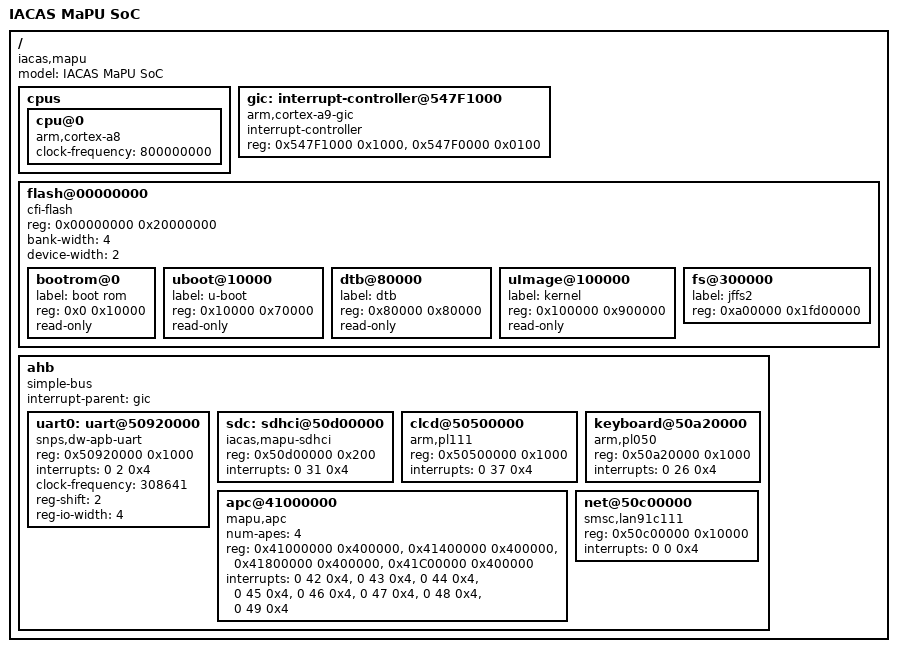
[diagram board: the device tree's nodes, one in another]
/*
 *  Copyright (C) 2014 IACAS, Lei Wang
 *
 * This software is licensed under the terms of the GNU General Public
 * License version 2, as published by the Free Software Foundation, and
 * may be copied, distributed, and modified under those terms.
 *
 * This program is distributed in the hope that it will be useful,
 * but WITHOUT ANY WARRANTY; without even the implied warranty of
 * MERCHANTABILITY or FITNESS FOR A PARTICULAR PURPOSE.  See the
 * GNU General Public License for more details.
 */
/dts-v1/;
/include/ "skeleton.dtsi"
/ {
	model = "IACAS MaPU SoC";
	compatible = "iacas,mapu";
	#address-cells = <1>;
	#size-cells = <1>;

	cpus {
		#address-cells = <1>;
		#size-cells = <0>;

		cpu@0 {
			compatible = "arm,cortex-a8";
			clock-frequency = <800000000>;
		};
	};

  gic: interrupt-controller@547F1000 {
		compatible = "arm,cortex-a9-gic";
		interrupt-controller;
		#interrupt-cells = <3>;
		reg = <0x547F1000 0x1000>,
			    <0x547F0000 0x0100>;
	};
	
	flash@00000000 {
		compatible = "cfi-flash";
		reg = <0x00000000 0x20000000>;
		bank-width = <4>;
		device-width = <2>;
		#address-cells = <1>;
		#size-cells = <1>;
		bootrom@0 {
			label = "boot rom";
			reg = <0x0 0x10000>;
			read-only;
		};
		uboot@10000 {
			label ="u-boot";
			reg = <0x10000 0x70000>;
			read-only;
		};
		dtb@80000 {
			label ="dtb";
			reg = <0x80000 0x80000>;
			read-only;
		};
		uImage@100000 {
			label ="kernel";
			reg = <0x100000 0x900000>;
			read-only;
		};
		fs@300000 {
			label ="jffs2";
			reg = <0xa00000 0x1fd00000>;
		};
	};
	
	ahb {
		compatible = "simple-bus";
		#address-cells = <1>;
		#size-cells = <1>;
    interrupt-parent = <&gic>;
		ranges;
/*
	  uart0: uart@50900000 {
		  compatible = "snps,dw-apb-uart";
		  reg = <0x50900000 0x1000>;
		  interrupts = <0 2 0x4>;
		  clock-frequency = <308641>;
		  reg-shift = <2>;
			reg-io-width = <4>;
		};
*/
/* Match MaPU chip*/
    uart0: uart@50920000 {
      compatible = "snps,dw-apb-uart";
      reg = <0x50920000 0x1000>;
      interrupts = <0 2 0x4>;
      clock-frequency = <308641>;
      reg-shift = <2>;
      reg-io-width = <4>;
    };
    sdc: sdhci@50d00000 {
	    compatible = "iacas,mapu-sdhci";
	    reg = <0x50d00000 0x200>;
			interrupts = <0 31 0x4>;
		};
  
    clcd@50500000 {
      compatible = "arm,pl111", "arm,primecell";
      reg = <0x50500000 0x1000>;
      interrupts = <0 37 0x4>;
    };
    
    keyboard@50a20000 {
      compatible = "arm,pl050", "arm,primecell";
      reg = <0x50a20000 0x1000>;
      interrupts = <0 26 0x4>;
    };
    
    apc@41000000 {
      compatible = "mapu,apc";
      num-apes = <4>;
      reg = <0x41000000 0x400000>, <0x41400000 0x400000>, <0x41800000 0x400000>, <0x41C00000 0x400000>;
      interrupts = <0 42 0x4>, <0 43 0x4>, <0 44 0x4>, <0 45 0x4>, <0 46 0x4>, <0 47 0x4>, <0 48 0x4>, <0 49 0x4>;
    };
    
    net@50c00000 {
      compatible = "smsc,lan91c111";
      reg = <0x50c00000 0x10000>;
      interrupts = <0 0 0x4>;
    };
	};
};
